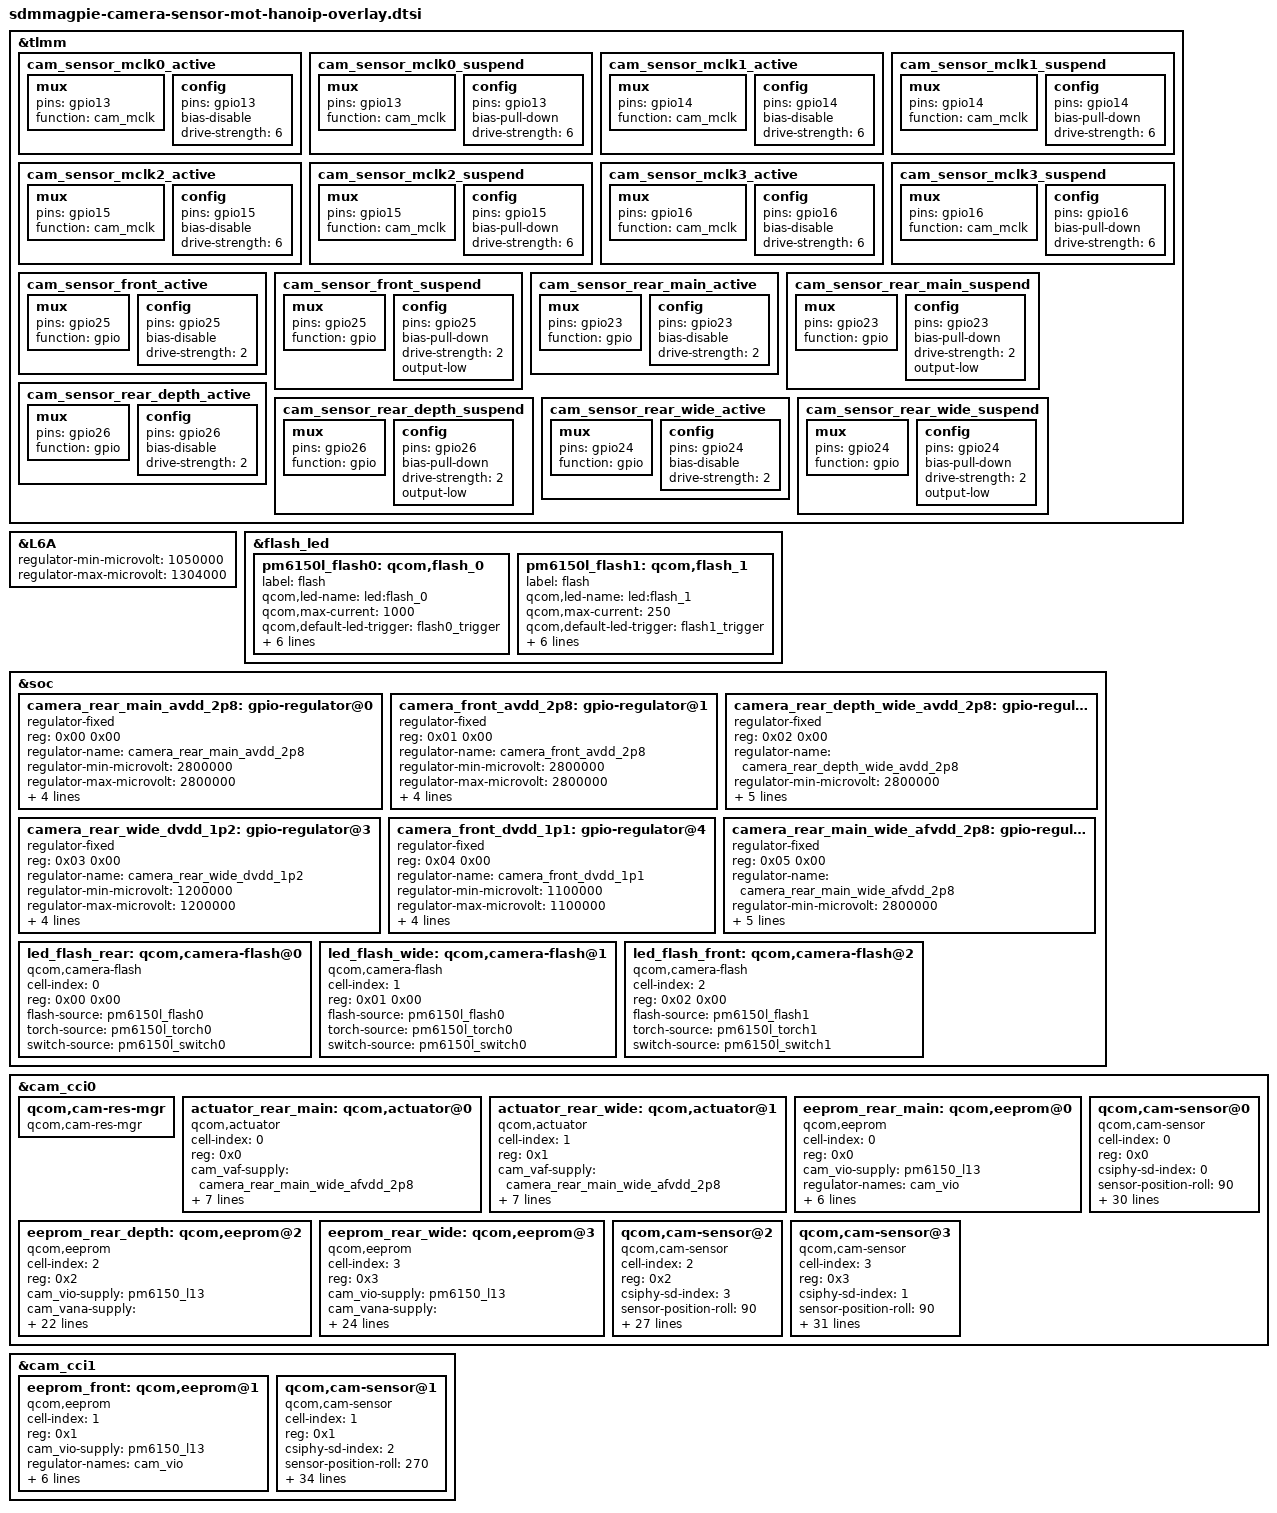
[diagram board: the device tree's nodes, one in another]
/*
 * Copyright (c) 2018-2019, The Linux Foundation. All rights reserved.
 *
 * This program is free software; you can redistribute it and/or modify
 * it under the terms of the GNU General Public License version 2 and
 * only version 2 as published by the Free Software Foundation.
 *
 * This program is distributed in the hope that it will be useful,
 * but WITHOUT ANY WARRANTY; without even the implied warranty of
 * MERCHANTABILITY or FITNESS FOR A PARTICULAR PURPOSE.  See the
 * GNU General Public License for more details.
 */
&tlmm {
/*MCLKs*/
	cam_sensor_mclk0_active: cam_sensor_mclk0_active {
		/* MCLK0 */
		mux {
			pins = "gpio13";
			function = "cam_mclk";
		};

		config {
			pins = "gpio13";
			bias-disable; /* No PULL */
			drive-strength = <6>; /* 6 MA */
		};
	};

	cam_sensor_mclk0_suspend: cam_sensor_mclk0_suspend {
		/* MCLK0 */
		mux {
			pins = "gpio13";
			function = "cam_mclk";
		};

		config {
			pins = "gpio13";
			bias-pull-down; /* PULL DOWN */
			drive-strength = <6>; /* 6 MA */
		};
	};

	cam_sensor_mclk1_active: cam_sensor_mclk1_active {
		/* MCLK1 */
		mux {
			pins = "gpio14";
			function = "cam_mclk";
		};

		config {
			pins = "gpio14";
			bias-disable; /* No PULL */
			drive-strength = <6>; /* 6 MA */
		};
	};

	cam_sensor_mclk1_suspend: cam_sensor_mclk1_suspend {
		/* MCLK1 */
		mux {
			pins = "gpio14";
			function = "cam_mclk";
		};

		config {
			pins = "gpio14";
			bias-pull-down; /* PULL DOWN */
			drive-strength = <6>; /* 6 MA */
		};
	};

	cam_sensor_mclk2_active: cam_sensor_mclk2_active {
		/* MCLK2 */
		mux {
			pins = "gpio15";
			function = "cam_mclk";
		};

		config {
			pins = "gpio15";
			bias-disable; /* No PULL */
			drive-strength = <6>; /* 6 MA */
		};
	};

	cam_sensor_mclk2_suspend: cam_sensor_mclk2_suspend {
		/* MCLK2 */
		mux {
			pins = "gpio15";
			function = "cam_mclk";
		};

		config {
			pins = "gpio15";
			bias-pull-down; /* PULL DOWN */
			drive-strength = <6>; /* 6 MA */
		};
	};

	cam_sensor_mclk3_active: cam_sensor_mclk3_active {
		/* MCLK3 */
		mux {
			pins = "gpio16";
			function = "cam_mclk";
		};

		config {
			pins = "gpio16";
			bias-disable; /* No PULL */
			drive-strength = <6>; /* 6 MA */
		};
	};

	cam_sensor_mclk3_suspend: cam_sensor_mclk3_suspend {
		/* MCLK3 */
		mux {
			pins = "gpio16";
			function = "cam_mclk";
		};

		config {
			pins = "gpio16";
			bias-pull-down; /* PULL DOWN */
			drive-strength = <6>; /* 6 MA */
		};
	};
/*RESETs*/
	cam_sensor_front_active: cam_sensor_front_active {
		/* CAM2_RST  */
		mux {
			pins = "gpio25";
			function = "gpio";
		};

		config {
			pins = "gpio25";
			bias-disable; /* No PULL */
			drive-strength = <2>; /* 2 MA */
		};
	};

	cam_sensor_front_suspend: cam_sensor_front_suspend {
		/* CAM2_RST */
		mux {
			pins = "gpio25";
			function = "gpio";
		};

		config {
			pins = "gpio25";
			bias-pull-down; /* PULL DOWN */
			drive-strength = <2>; /* 2 MA */
			output-low;
		};
	};

	cam_sensor_rear_main_active: cam_sensor_rear_main_active {
		/* CAM0_RST  */
		mux {
			pins = "gpio23";
			function = "gpio";
		};

		config {
			pins = "gpio23";
			bias-disable; /* No PULL */
			drive-strength = <2>; /* 2 MA */
		};
	};

	cam_sensor_rear_main_suspend: cam_sensor_rear_main_suspend {
		/* CAM0_RST */
		mux {
			pins = "gpio23";
			function = "gpio";
		};

		config {
			pins = "gpio23";
			bias-pull-down; /* PULL DOWN */
			drive-strength = <2>; /* 2 MA */
			output-low;
		};
	};

	cam_sensor_rear_depth_active: cam_sensor_rear_depth_active {
		/* CAM3_RST  */
		mux {
			pins = "gpio26";
			function = "gpio";
		};

		config {
			pins = "gpio26";
			bias-disable; /* No PULL */
			drive-strength = <2>; /* 2 MA */
		};
	};

	cam_sensor_rear_depth_suspend: cam_sensor_rear_depth_suspend {
		/* CAM3_RST */
		mux {
			pins = "gpio26";
			function = "gpio";
		};

		config {
			pins = "gpio26";
			bias-pull-down; /* PULL DOWN */
			drive-strength = <2>; /* 2 MA */
			output-low;
		};
	};

	cam_sensor_rear_wide_active: cam_sensor_rear_wide_active {
		/* CAM1_RST  */
		mux {
			pins = "gpio24";
			function = "gpio";
		};

		config {
			pins = "gpio24";
			bias-disable; /* No PULL */
			drive-strength = <2>; /* 2 MA */
		};
	};

	cam_sensor_rear_wide_suspend: cam_sensor_rear_wide_suspend {
		/* CAM1_RST */
		mux {
			pins = "gpio24";
			function = "gpio";
		};

		config {
			pins = "gpio24";
			bias-pull-down; /* PULL DOWN */
			drive-strength = <2>; /* 2 MA */
			output-low;
		};
	};
};

&L6A {
	regulator-min-microvolt = <1050000>;
	regulator-max-microvolt = <1304000>;
};

&flash_led {
	pm6150l_flash0: qcom,flash_0 {
		label = "flash";
		qcom,led-name = "led:flash_0";
		qcom,max-current = <1000>;
		qcom,default-led-trigger = "flash0_trigger";
		qcom,id = <0>;
		qcom,current-ma = <500>;
		qcom,duration-ms = <1280>;
		qcom,ires-ua = <12500>;
		qcom,hdrm-voltage-mv = <325>;
		qcom,hdrm-vol-hi-lo-win-mv = <100>;
	};

	pm6150l_flash1: qcom,flash_1 {
		label = "flash";
		qcom,led-name = "led:flash_1";
		qcom,max-current = <250>;
		qcom,default-led-trigger = "flash1_trigger";
		qcom,id = <1>;
		qcom,current-ma = <100>;
		qcom,duration-ms = <1280>;
		qcom,ires-ua = <12500>;
		qcom,hdrm-voltage-mv = <325>;
		qcom,hdrm-vol-hi-lo-win-mv = <100>;
	};
};

&soc {
/*regulators*/
	camera_rear_main_avdd_2p8: gpio-regulator@0 {
		/* REAR_CAM_AVDD_2P8*/
		compatible = "regulator-fixed";
		reg = <0x00 0x00>;
		regulator-name = "camera_rear_main_avdd_2p8";
		regulator-min-microvolt = <2800000>;
		regulator-max-microvolt = <2800000>;
		regulator-enable-ramp-delay = <233>;
		enable-active-high;
		gpio = <&tlmm 72 0>; /* CAM_F_AVDD_EN*/
		vin-supply = <&pm6150l_bob>; /* VREG_BOB*/
	};

	camera_front_avdd_2p8: gpio-regulator@1 {
		/* FRONT_CAM_AVDD_2P8*/
		compatible = "regulator-fixed";
		reg = <0x01 0x00>;
		regulator-name = "camera_front_avdd_2p8";
		regulator-min-microvolt = <2800000>;
		regulator-max-microvolt = <2800000>;
		regulator-enable-ramp-delay = <233>;
		enable-active-high;
		gpio = <&tlmm 65 0>; /* CAM_R_AVDD_EN*/
		vin-supply = <&pm6150l_bob>; /* VREG_BOB*/
	};

	camera_rear_depth_wide_avdd_2p8: gpio-regulator@2 {
		/* SLAVE_CAM_AVDD_2P8*/
		compatible = "regulator-fixed";
		reg = <0x02 0x00>;
		regulator-name = "camera_rear_depth_wide_avdd_2p8";
		regulator-min-microvolt = <2800000>;
		regulator-max-microvolt = <2800000>;
		regulator-enable-ramp-delay = <233>;
		enable-active-high;
		gpio = <&tlmm 46 0>; /* CAM_S_AVDD_EN*/
		vin-supply = <&pm6150l_bob>; /* VREG_BOB*/
	};

	camera_rear_wide_dvdd_1p2: gpio-regulator@3 {
		/* CAM_1P2_DVDD*/
		compatible = "regulator-fixed";
		reg = <0x03 0x00>;
		regulator-name = "camera_rear_wide_dvdd_1p2";
		regulator-min-microvolt = <1200000>;
		regulator-max-microvolt = <1200000>;
		regulator-enable-ramp-delay = <233>;
		enable-active-high;
		gpio = <&tlmm 33 0>; /* CAM_S_DVDD_EN*/
		vin-supply = <&pm6150l_s8>; /* VREG_S8C_1P35*/ /*bias: VREG_BOB*/
	};

	camera_front_dvdd_1p1: gpio-regulator@4 {
		/* CAM_1P2_DVDD*/
		compatible = "regulator-fixed";
		reg = <0x04 0x00>;
		regulator-name = "camera_front_dvdd_1p1";
		regulator-min-microvolt = <1100000>;
		regulator-max-microvolt = <1100000>;
		regulator-enable-ramp-delay = <233>;
		enable-active-high;
		gpio = <&tlmm 93 0>; /* CAM_F_DVDD_EN*/
		vin-supply = <&pm6150l_s8>; /* VREG_S8C_1P35*/ /*bias: VREG_BOB*/
	};

	camera_rear_main_wide_afvdd_2p8: gpio-regulator@5 {
		/*CAM_AFVCC_2P8*/
		compatible = "regulator-fixed";
		reg = <0x05 0x00>;
		regulator-name = "camera_rear_main_wide_afvdd_2p8";
		regulator-min-microvolt = <2800000>;
		regulator-max-microvolt = <2800000>;
		regulator-enable-ramp-delay = <233>;
		enable-active-high;
		gpio = <&tlmm 64 0>; /* CAM_R_AFVDD_EN*/
		vin-supply = <&pm6150l_bob>; /*VREG_BOB*/
	};

	led_flash_rear: qcom,camera-flash@0 {
		cell-index = <0>;
		reg = <0x00 0x00>;
		compatible = "qcom,camera-flash";
		flash-source = <&pm6150l_flash0>;
		torch-source = <&pm6150l_torch0>;
		switch-source = <&pm6150l_switch0>;
		status = "ok";
	};

	led_flash_wide: qcom,camera-flash@1 {
		cell-index = <1>;
		reg = <0x01 0x00>;
		compatible = "qcom,camera-flash";
		flash-source = <&pm6150l_flash0>;
		torch-source = <&pm6150l_torch0>;
		switch-source = <&pm6150l_switch0>;
		status = "ok";
	};

	led_flash_front: qcom,camera-flash@2 {
		cell-index = <2>;
		reg = <0x02 0x00>;
		compatible = "qcom,camera-flash";
		flash-source = <&pm6150l_flash1>;
		torch-source = <&pm6150l_torch1>;
		switch-source = <&pm6150l_switch1>;
		status = "ok";
	};
};

&cam_cci0 {
	qcom,cam-res-mgr {
		compatible = "qcom,cam-res-mgr";
		status = "ok";
	};

	actuator_rear_main: qcom,actuator@0 {
		cell-index = <0>;
		reg = <0x0>;
		compatible = "qcom,actuator";
		cam_vaf-supply = <&camera_rear_main_wide_afvdd_2p8>;
		regulator-names = "cam_vaf";
		rgltr-cntrl-support;
		rgltr-min-voltage = <2800000>;
		rgltr-max-voltage = <2800000>;
		rgltr-load-current = <0>;
		cci-device = <0>;
		cci-master = <0>;
		status = "ok";
	};

	actuator_rear_wide: qcom,actuator@1 {
		cell-index = <1>;
		reg = <0x1>;
		compatible = "qcom,actuator";
		cam_vaf-supply = <&camera_rear_main_wide_afvdd_2p8>;
		regulator-names = "cam_vaf";
		rgltr-cntrl-support;
		rgltr-min-voltage = <2800000>;
		rgltr-max-voltage = <2800000>;
		rgltr-load-current = <0>;
		cci-device = <0>;
		cci-master = <1>;
		status = "ok";
	};

	eeprom_rear_main: qcom,eeprom@0 {
		cell-index = <0>;
		reg = <0x0>;
		compatible = "qcom,eeprom";
		cam_vio-supply = <&pm6150_l13>;
		regulator-names = "cam_vio";
		rgltr-cntrl-support;
		rgltr-min-voltage = <1800000>;
		rgltr-max-voltage = <1800000>;
		rgltr-load-current = <0>;
		cci-device = <0>;
		cci-master = <0>;
		status = "ok";
	};

	eeprom_rear_depth: qcom,eeprom@2 {
		cell-index = <2>;
		reg = <0x2>;
		compatible = "qcom,eeprom";
		cam_vio-supply = <&pm6150_l13>;
		cam_vana-supply = <&camera_rear_depth_wide_avdd_2p8>;
		cam_clk-supply = <&titan_top_gdsc>;
		regulator-names = "cam_vio", "cam_vana", "cam_clk";
		rgltr-cntrl-support;
		rgltr-min-voltage = <1800000 2800000 0>;
		rgltr-max-voltage = <1800000 2800000 0>;
		rgltr-load-current = <0 80000 0>;
		gpio-no-mux = <0>;
		pinctrl-names = "cam_default", "cam_suspend";
		pinctrl-0 = <&cam_sensor_mclk3_active
				&cam_sensor_rear_depth_active>;
		pinctrl-1 = <&cam_sensor_mclk3_suspend
				&cam_sensor_rear_depth_suspend>;
		gpios = <&tlmm 16 0>,
			<&tlmm 26 0>;
		gpio-reset = <1>;
		gpio-req-tbl-num = <0 1>;
		gpio-req-tbl-flags = <1 0>;
		gpio-req-tbl-label = "CAMIF_MCLK3", "CAM_RESET3";
		cci-device = <0>;
		cci-master = <1>;
		status = "ok";
		clocks = <&clock_camcc CAM_CC_MCLK3_CLK>;
		clock-names = "cam_clk";
		clock-cntl-level = "turbo";
		clock-rates = <24000000>;
	};

	eeprom_rear_wide: qcom,eeprom@3 {
		cell-index = <3>;
		reg = <0x3>;
		compatible = "qcom,eeprom";
		cam_vio-supply = <&pm6150_l13>;
		cam_vana-supply = <&camera_rear_depth_wide_avdd_2p8>;
		cam_vdig-supply = <&camera_rear_wide_dvdd_1p2>;
		cam_clk-supply = <&titan_top_gdsc>;
		regulator-names = "cam_vio", "cam_vana", "cam_vdig", "cam_clk";
		rgltr-cntrl-support;
		rgltr-min-voltage = <1800000 2800000 1200000 0>;
		rgltr-max-voltage = <1800000 2800000 1200000 0>;
		rgltr-load-current = <0 80000 105000 0>;
		gpio-no-mux = <0>;
		pinctrl-names = "cam_default", "cam_suspend";
		pinctrl-0 = <&cam_sensor_mclk1_active
				&cam_sensor_rear_wide_active>;
		pinctrl-1 = <&cam_sensor_mclk1_suspend
				&cam_sensor_rear_wide_suspend>;
		gpios = <&tlmm 14 0>,
			<&tlmm 24 0>;
		gpio-reset = <1>;
		gpio-req-tbl-num = <0 1>;
		gpio-req-tbl-flags = <1 0>;
		gpio-req-tbl-label = "CAMIF_MCLK1", "CAM_RESET1";
		cci-device = <0>;
		cci-master = <1>;
		status = "ok";
		clocks = <&clock_camcc CAM_CC_MCLK1_CLK>;
		clock-names = "cam_clk";
		clock-cntl-level = "turbo";
		clock-rates = <24000000>;
	};
	qcom,cam-sensor@0 {
		/*rear main S5KHM2 compatable OV64B*/
		cell-index = <0>;
		compatible = "qcom,cam-sensor";
		reg = <0x0>;
		csiphy-sd-index = <0>;
		sensor-position-roll = <90>;
		sensor-position-pitch = <0>;
		sensor-position-yaw = <180>;
		eeprom-src = <&eeprom_rear_main>;
		actuator-src = <&actuator_rear_main>;
		led-flash-src = <&led_flash_rear>;
		cam_vio-supply = <&pm6150_l13>;
		cam_vana-supply = <&camera_rear_main_avdd_2p8>;
		cam_vdig-supply = <&pm6150_l6>;
		cam_clk-supply = <&titan_top_gdsc>;
		regulator-names = "cam_vio", "cam_vana", "cam_vdig", "cam_clk";
		rgltr-cntrl-support;
		rgltr-min-voltage = <1800000 2800000 1050000 0>;
		rgltr-max-voltage = <1800000 2800000 1100000 0>;
		rgltr-load-current = <0 80000 105000 0>;
		gpio-no-mux = <0>;
		pinctrl-names = "cam_default", "cam_suspend";
		pinctrl-0 = <&cam_sensor_mclk0_active
				&cam_sensor_rear_main_active>;
		pinctrl-1 = <&cam_sensor_mclk0_suspend
				&cam_sensor_rear_main_suspend>;
		gpios = <&tlmm 13 0>,
			<&tlmm 23 0>;
		gpio-reset = <1>;
		gpio-req-tbl-num = <0 1>;
		gpio-req-tbl-flags = <1 0>;
		gpio-req-tbl-label = "CAMIF_MCLK0", "CAM_RESET0";
		cci-device = <0>;
		cci-master = <0>;
		status = "ok";
		clocks = <&clock_camcc CAM_CC_MCLK0_CLK>;
		clock-names = "cam_clk";
		clock-cntl-level = "turbo";
		clock-rates = <24000000>;
	};

	qcom,cam-sensor@2 {
		/*rear depth ov02b1b*/
		cell-index = <2>;
		compatible = "qcom,cam-sensor";
		reg = <0x2>;
		csiphy-sd-index = <3>;
		sensor-position-roll = <90>;
		sensor-position-pitch = <0>;
		sensor-position-yaw = <180>;
		eeprom-src = <&eeprom_rear_depth>;
		cam_vio-supply = <&pm6150_l13>;
		cam_vana-supply = <&camera_rear_depth_wide_avdd_2p8>;
		cam_clk-supply = <&titan_top_gdsc>;
		regulator-names = "cam_vio", "cam_vana", "cam_clk";
		rgltr-cntrl-support;
		rgltr-min-voltage = <1800000 2800000 0>;
		rgltr-max-voltage = <1800000 2800000 0>;
		rgltr-load-current = <0 80000 0>;
		gpio-no-mux = <0>;
		pinctrl-names = "cam_default", "cam_suspend";
		pinctrl-0 = <&cam_sensor_mclk3_active
				&cam_sensor_rear_depth_active>;
		pinctrl-1 = <&cam_sensor_mclk3_suspend
				&cam_sensor_rear_depth_suspend>;
		gpios = <&tlmm 16 0>,
			<&tlmm 26 0>;
		gpio-reset = <1>;
		gpio-req-tbl-num = <0 1>;
		gpio-req-tbl-flags = <1 0>;
		gpio-req-tbl-label = "CAMIF_MCLK3", "CAM_RESET3";
		cci-device = <0>;
		cci-master = <1>;
		status = "ok";
		clocks = <&clock_camcc CAM_CC_MCLK3_CLK>;
		clock-names = "cam_clk";
		clock-cntl-level = "turbo";
		clock-rates = <24000000>;
	};

	qcom,cam-sensor@3 {
		/*rear wide s5k4h7*/
		cell-index = <3>;
		compatible = "qcom,cam-sensor";
		reg = <0x3>;
		csiphy-sd-index = <1>;
		sensor-position-roll = <90>;
		sensor-position-pitch = <0>;
		sensor-position-yaw = <180>;
		eeprom-src = <&eeprom_rear_wide>;
		actuator-src = <&actuator_rear_wide>;
		led-flash-src = <&led_flash_wide>;
		cam_vio-supply = <&pm6150_l13>;
		cam_vana-supply = <&camera_rear_depth_wide_avdd_2p8>;
		cam_vdig-supply = <&camera_rear_wide_dvdd_1p2>;
		cam_clk-supply = <&titan_top_gdsc>;
		regulator-names = "cam_vio", "cam_vana", "cam_vdig", "cam_clk";
		rgltr-cntrl-support;
		rgltr-min-voltage = <1800000 2800000 1200000 0>;
		rgltr-max-voltage = <1800000 2800000 1200000 0>;
		rgltr-load-current = <0 80000 105000 0>;
		gpio-no-mux = <0>;
		pinctrl-names = "cam_default", "cam_suspend";
		pinctrl-0 = <&cam_sensor_mclk1_active
				&cam_sensor_rear_wide_active>;
		pinctrl-1 = <&cam_sensor_mclk1_suspend
				&cam_sensor_rear_wide_suspend>;
		gpios = <&tlmm 14 0>,
			<&tlmm 24 0>;
		gpio-reset = <1>;
		gpio-req-tbl-num = <0 1>;
		gpio-req-tbl-flags = <1 0>;
		gpio-req-tbl-label = "CAMIF_MCLK1", "CAM_RESET1";
		cci-device = <0>;
		cci-master = <1>;
		status = "ok";
		clocks = <&clock_camcc CAM_CC_MCLK1_CLK>;
		clock-names = "cam_clk";
		clock-cntl-level = "turbo";
		clock-rates = <24000000>;
	};
};

&cam_cci1 {

	eeprom_front: qcom,eeprom@1 {
		cell-index = <1>;
		reg = <0x1>;
		compatible = "qcom,eeprom";
		cam_vio-supply = <&pm6150_l13>;
		regulator-names = "cam_vio";
		rgltr-cntrl-support;
		rgltr-min-voltage = <1800000>;
		rgltr-max-voltage = <1800000>;
		rgltr-load-current = <0>;
		cci-device = <1>;
		cci-master = <0>;
		status = "ok";
	};

	qcom,cam-sensor@1 {
		/*front compatabl ov16a1q and ov32b*/
		cell-index = <1>;
		compatible = "qcom,cam-sensor";
		reg = <0x1>;
		csiphy-sd-index = <2>;
		sensor-position-roll = <270>;
		sensor-position-pitch = <0>;
		sensor-position-yaw = <0>;
		led-flash-src = <&led_flash_front>;
		eeprom-src = <&eeprom_front>;
		cam_vio-supply = <&pm6150_l13>;
		cam_vana-supply = <&camera_front_avdd_2p8>;
		cam_vdig-supply = <&camera_front_dvdd_1p1>;/* For ov32b */
		cam_v_custom1-supply = <&camera_rear_wide_dvdd_1p2>; /* For ov16a1q */
		cam_clk-supply = <&titan_top_gdsc>;
		regulator-names = "cam_vio", "cam_vana", "cam_vdig", "cam_v_custom1", "cam_clk";
		rgltr-cntrl-support;
		rgltr-min-voltage = <1800000 2800000 1100000 1200000 0>;
		rgltr-max-voltage = <1800000 2800000 1100000 1200000 0>;
		rgltr-load-current = <0 80000 105000 105000 0>;
		gpio-no-mux = <0>;
		pinctrl-names = "cam_default", "cam_suspend";
		pinctrl-0 = <&cam_sensor_mclk2_active
				&cam_sensor_front_active>;
		pinctrl-1 = <&cam_sensor_mclk2_suspend
				&cam_sensor_front_suspend>;
		gpios = <&tlmm 15 0>,
			<&tlmm 25 0>;
		gpio-reset = <1>;
		gpio-req-tbl-num = <0 1>;
		gpio-req-tbl-flags = <1 0>;
		gpio-req-tbl-label = "CAMIF_MCLK2", "CAM_RESET2";
		sensor-mode = <1>;
		cci-device = <1>;
		cci-master = <0>;
		status = "ok";
		clocks = <&clock_camcc CAM_CC_MCLK2_CLK>;
		clock-names = "cam_clk";
		clock-cntl-level = "turbo";
		clock-rates = <24000000>;
	};
};
